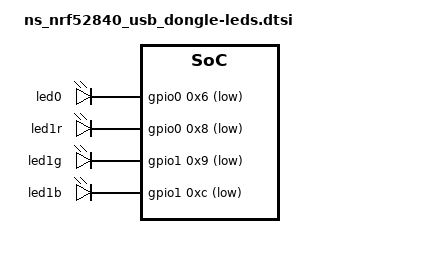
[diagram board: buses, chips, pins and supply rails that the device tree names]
//
// gp-nrf-ble-blinky
// Copyright (c) 2023, Greg PFISTER. MIT Licennse
//
// THE SOFTWARE IS PROVIDED "AS IS", WITHOUT WARRANTY OF ANY KIND, EXPRESS OR
// IMPLIED, INCLUDING BUT NOT LIMITED TO THE WARRANTIES OF MERCHANTABILITY,
// FITNESS FOR A PARTICULAR PURPOSE AND NONINFRINGEMENT.IN NO EVENT SHALL THE
// AUTHORS OR COPYRIGHT HOLDERS BE LIABLE FOR ANY CLAIM, DAMAGES OR OTHER
// LIABILITY, WHETHER IN AN ACTION OF CONTRACT, TORT OR OTHERWISE, ARISING FROM,
// OUT OF OR IN CONNECTION WITH THE SOFTWARE OR THE USE OR OTHER DEALINGS IN THE
// SOFTWARE.
//

/ {

	aliases {
		ledblinky = &led0;
		ledbtstatusr = &led1r;
		ledbtstatusg = &led1g;
		ledbtstatusb = &led1b;
	};

	leds {
		compatible = "gpio-leds";
        led0: led_0 { // The blinky led
            gpios = < &gpio0 0x6 0x1 >;
        };
        led1r: led_1r {
            gpios = < &gpio0 0x8 0x1 >;// The BT status led
        };
        led1g: led_1g {
            gpios = < &gpio1 0x9 0x1 >;// The BT status led
        };
        led1b: led_1b {
            gpios = < &gpio1 0xc 0x1 >;// The BT status led
        };

    };
};
